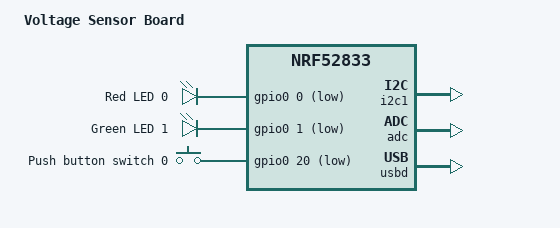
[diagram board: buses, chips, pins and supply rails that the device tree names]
/*
 * Copyright (c) 2021 Nordic Semiconductor ASA
 * SPDX-License-Identifier: Apache-2.0
 */

/dts-v1/;
#include <nordic/nrf52833_qdaa.dtsi>
#include "voltage_sensor-pinctrl.dtsi"
#include <zephyr/dt-bindings/input/input-event-codes.h>

/ {
	model = "Voltage Sensor Board";
	compatible = "vendor,voltage-sensor-board";

	chosen {
		zephyr,console = &uart0;
		zephyr,sram = &sram0;
		zephyr,flash = &flash0;
	};
	leds {
		compatible = "gpio-leds";
		led0: led_0 {
			gpios = <&gpio0 0 GPIO_ACTIVE_LOW>;
			label = "Red LED 0";
		};
		led1: led_1 {
			gpios = <&gpio0 1 GPIO_ACTIVE_LOW>;
			label = "Green LED 1";
		};
	};
	buttons {
		compatible = "gpio-keys";
		button0: button_0 {
			gpios = <&gpio0 20 (GPIO_PULL_UP | GPIO_ACTIVE_LOW)>;
			label = "Push button switch 0";
			zephyr,code = <INPUT_KEY_0>;
		};
	};
	aliases {
		led0 = &led0;
		led1 = &led1;
		sw0 = &button0;
		bootloader-led0 = &led0;
		mcuboot-button0 = &button0;
		mcuboot-led0 = &led0;
		watchdog0 = &wdt0;
	};
};

&gpio0 {
	status = "okay";
};

&uart0 {
	compatible = "nordic,nrf-uarte";
	status = "disabled";

	current-speed = <115200>;
	pinctrl-0 = <&uart0_default>;
	pinctrl-1 = <&uart0_sleep>;
	pinctrl-names = "default", "sleep";
};

&i2c1 {
	compatible = "nordic,nrf-twi";
	status = "okay";
	pinctrl-0 = <&i2c1_default>;
	pinctrl-1 = <&i2c1_sleep>;
	pinctrl-names = "default", "sleep";
};

&adc {
	status = "okay";
};

zephyr_udc0: &usbd {
	compatible = "nordic,nrf-usbd";
	status = "okay";
};
